# wl_phy_tx_secure register map
Vendor: Texas Instruments
Peripheral module from a debugger description file (folder CC35X1E).
Registers are 32-bit, access per field, reset 0x0 unless marked. A register's access mark holds for its fields unless they carry their own. Offsets are as the file gives them; lines under a group give offsets from that group; [hi:lo] are bit positions; {n}, {i} and the like mark numbered series; 'fields as' and 'values as' point back to an identical list; <NAME> marks a mode.

## wl_phy_tx_secure (part 1 of 2)
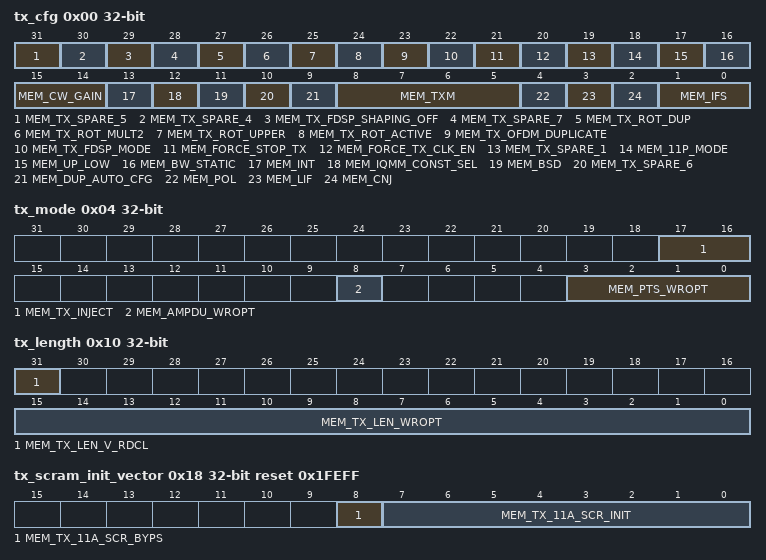
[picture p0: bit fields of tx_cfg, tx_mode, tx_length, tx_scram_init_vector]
0x00 tx_cfg rw reset not defined — Transmitter Configuration (TX_CFG) (0x1000)
  [31] MEM_TX_SPARE_5
  [30] MEM_TX_SPARE_4
  [29] MEM_TX_FDSP_SHAPING_OFF — An FDSP indication of whether to use spectral shaping or not. 0 - Spectral Shaping Enabled 1 - Spectral Shaping Disabled
  [28] MEM_TX_SPARE_7 — formerly: mem_tx_beamforming This bit is connected to the FDSP, and affects its behavior. Any other effect is TBD. 0 - Beamforming is off 1 - Beamforming is on
  [27] MEM_TX_ROT_DUP — Controls the 11b rotator. 0 - Tx LPM Regular: exp(2*pi*j*f*t) 1 - Tx LPM Duplication: cos(2*pi*f*t) Also known as lpm_sup_pos_mode
  [26] MEM_TX_ROT_MULT2 — Controls the 11b rotator. 0 - Tx LPM regular mode 1 - Tx LPM multiplies output by 2 (shift left one bit)
  [25] MEM_TX_ROT_UPPER — Controls the 11b rotator. 0 - Lower: The Tx LPM applies a -10 MHz frequency shift on the 11b signal 1 - Upper: The Tx LPM applies a +10 MHz frequency shift on the 11b signal
  [24] MEM_TX_ROT_ACTIVE — Controls the 11b rotator. 0 - The Tx LPM is Bypassed 1 - The Tx LPM is Active - Moves 11b to either upper (+10MHz) or lower (-10MHz)
  [23] MEM_TX_OFDM_DUPLICATE — Controls duplication of 20MHz OFDM signals in 40MHz channels. 0 - Either upper or lower. The other channel will be silent. 1 - Duplicate 20MHz signal to both upper and lower. According to the 11n standard, duplication of 20MHz wide OFDM signals is allowed in MCS32, and maybe for legacy (11a/g) signals too. The tx_ofdm_duplicate feature is not supported in 20MHz channels and for 40MHz wide 11n rates. It's not clear whether duplicating 11b signals is allowed. If required, use the mem_tx_rot_dup bit in this register (tx_cfg), since 11b is not an OFDM signal.
  [22] MEM_TX_FDSP_MODE — Select Tx FDSP mode or debug mode. 0 - The Tx OFDM will operate in debug mode. The Tx HW will transfer bins directly into the FFT, bypassing the FDSP and pre-FFT RAM. 1 - The Tx OFDM will operate in FDSP mode. The FDSP will process and send the bins to the FFT, through the pre-FFT RAM.
  [21] MEM_FORCE_STOP_TX — force_stop_tx - When force_stop_tx is asserted high the stop_tx is asserted. This bit is not self-clearing and the stop_tx will stay high until force_stop_tx is set back to 0. This feature can be useful in an attempt to reset the Tx-PHY, especially when a packet is not being transmitted. Can be used in conjuction with the force_tx_clk_en in order to make sure that clk_mod_80 is running while the stop_tx is being asserted.
  [20] MEM_FORCE_TX_CLK_EN — force_tx_clk_en - When force_tx_clk_en is asserted high the tx_clk_enable signal is asserted, which immediately turns on clk_mod_80, clk_mod_120 and clk_mod_60, which are the main Tx-PHY clocks. This bit is not self-clearing , meaning that the tx_clk_enable will stay high until force_tx_clk_en is set back to 0. The significance of this bit is that when the toggling of the Tx clock consumes a lot of power. The Tx module turns on the power automatically when a Tx packet is in progress, but for certain RAMs, like the Signal Generator's 'dwell' RAM, the mem_force_tx_clk_en bit may have to be temporarily set to 1. Remember to clear it to zero when finished.
  [19] MEM_TX_SPARE_1
  [18] MEM_11P_MODE — enable 11P mode where the transmit BW is only 10Mhz.
  [17] MEM_UP_LOW — When 40Mhz static BW is set with 20Mhz dynamic setting from MAC, this bit DEFINES where the 20Mhz BW is centered on the upper 10Mhz or lower 10Mhz of the all 40Mhz BW. 0 - Lower 20Mhz 1 - Upper 20Mhz
  [16] MEM_BW_STATIC — Static bandwidth setting based on the analog RF. 0 - 20Mhz BW. 1 - 40Mhz BW.
  [15:14] MEM_CW_GAIN — Controls the gain in CW mode 0 = x1/2 1= x1 2 = x2 3 = x4
  [13] MEM_INT — Enables the Interpolator if set to 1
  [12] MEM_IQMM_CONST_SEL — Selects whether IQ mismatch compensation and channel selection are obtained from tx_adi LUT or the fixed registers '0' - tx_adi LUT selection '1' - Register file constant selection ('override' values)
  [11] MEM_BSD — 802.11b Scrambler Disable Bit This bit is used to disable the scrambler in the 802.11b transmitter.0 - Scrambler is enabled.1 - Scrambler is disabled.
  [10] MEM_TX_SPARE_6 — A spare configuration bit for gate-level ECOs, or any other usage. ZZZZ Formerly the mem_BMS (see description below) ZZZZ IEEE 802.11b Length Field Select ZZZZ NOTE: This bit is no longer relevant. The read value is always '1'. ZZZZ The LENGTH field in the 802.11b header is specified in units of microseconds. This bit is used to select whether the PHY logic will convert the number of bytes and data rate into a value of microseconds. The alternative is to specify the microsecond value directly in register 0x100C. ZZZZ 0 - The hardware byte-to-usec converter (bytes2us) has been removed, so setting BMS to '0' is not allowed. ZZZZ 1 - Content of the MAC_LEGNTH_FIELD register (address 0x100C) is inserted into LENGTH field. The value must be calculated for every 11b packet.
  [9] MEM_DUP_AUTO_CFG — Selects between straightforward PHY configurations and automatic duplicate control for 11a/g and 11b according to the MAC's rate40 bit (mem_BW_wropt). 0 - Regular configuration; The user must set the mem_BW_wropt, mem_tx_ofdm_duplicate, mem_tx_rot_dup (and all other regs for that matter) dynamically (per packet), to choose between primary and duplicate. 1 - Automatic duplicate control for 11a/g and 11b according to the MAC's rate40 bit (mem_BW_wropt). In this mode - the values of the duplicate-Tx-control OCP-bits (mem_tx_ofdm_duplicate, mem_tx_rot_dup) are ignored for 11b and 11a/g frames. Duplicate transmission is, instead, controlled according to the mem_BW_wropt, as if it is the duplicate-tx--mode selection bit. This auto-config mechanism is necessary since the MAC/PHY interface doesn't have a duplicate-tx-mode control bit. This location in the tx_cfg OCP reg used to be: mem_BDO IEEE 802.11b Default Override When processing a packet using the 802.11b logic, the constraints of the IEEE 802.11b standard PPDU format may be disabled. Asserting this bit allows the use of register values to specify the SYNC field length, the SFD field content, and the scrambler seed.0 - Use IEEE 802.11b PPDU format.1 - Override default IEEE 802.11b PPDU format. Removed in Quattro.
  [8:5] MEM_TXM — Transmit Mode Select This field is used to determine the mode of transmitter operation. In addition to the normal transmission of packets, a number of test modes are also available to test operation of the 802.11a and 802.11b transmitters. 0000 - (M_IDLE) Idle mode. Used to disable the transmitter. This value may be written to terminate one of the other modes. 0001 - (M_TXDU) Enable the transmitter to process a PPDU. Normal operation. 0010 - (M_FDAC) Apply the forced register values (addresses 0x1047, 0x1048) to the I and Q DACs. There is a bug in the FORCE_DAC mode in the 1273 PG 1.0, so please do not use the FORCE_DAC mode without cosultation. 0011 - (M_TXPD) Carrier suppression mode. Used for testing the 802.11b transmitter. ( In 11a mode, this setting would transmit data which is programmed into the interleaver rams, but this option is no longer supported in the 1273 PG 1.0) 0100 - (M_TXCO) Transmit an 802.11a packet using constant data. Bits [15:8] of the SERVICE field register are applied to the input of the scrambler. 0101 - (M_TXCD) Transmit continuous data. Keep transmitting an 802.11a packet using continouos data. Bits [15:8] of the SERVICE field register are applied to the input of the scrambler. 0110 - (M_TXCW) Produce constant amplitude waves on data and pilot tone subcarriers. Used for testing the 802.11a transmitter. The guard interval must be set to 800ns in continuous wave mode, for the tones to be continuous on symbol boundaries. 0111 - Not supported in the 1273. This is the same as mode 0001, except that the transmitter clock starts running as soon as this value is written, and does not shut off after a packet has completed transmission. 1000 - Not suported in the 1273. (M_FFTS) FFT signal generator testmode. This mode is used to write signal data generated by the FFT module to the DACs.
  [4] MEM_POL — DAC Output Clock Polarity Select In the 1273 this bit is disconnected, therefore non-functional. This bit selects which edge of the clock is used to register transmitter outputs. 0 - Use positive clock edge to register output. 1 - Use negative clock edge to register output.
  [3] MEM_LIF — Low IF Centers the Transmitted output signal on 20MHz, instead of on the normal Zero-IF. During Low-IF - the I-output contains the low-IF modulated signal, while the Q-output is held at zero. Note - the Tx--Low-IF mode is incompatble with the Rx-Low-IF mode, which is centered on 5MHz.
  [2] MEM_CNJ — Conjugate Output Data Select This bit is used to select between the normal output to the DACs and one that is a conjugate of the complex number represented by the I and Q outputs.0 - Selects normal output to DACs.1 - Selects complex conjugate output to DACs.
  [1:0] MEM_IFS — MAC Interface Data Rate Control These bits determine the maximum rate of data byte transfer at the MAC interface. This only has an effect on 802.11a transmissions since the 802.11b data rates are much lower than those specified here. The control bits specify the rate as follows: 00 - 10 Mbytes per second 01 - 13 Mbytes per second 10 - RESERVED 11 - RESERVED
0x04 tx_mode — Transmitter Mode (TX_MODE) (0x1008) The TX_MODE register is a class 1 register. It must be valid before the Tx-PHY receives a start_tx signal. The Tx-PHY is triggered by a PreTx-to-Tx transition on the phy_mode wire, so the TX_MODE register must be written valid before that transition.
  [17:16] MEM_TX_INJECT rw — 0 - no inject, 1 - inject resampler in (40Mhz), 2- inject resampler out "
  [8] MEM_AMPDU_WROPT rw — Aggregated MPDU is transmitted in this PPDU.
  [3:0] MEM_PTS_WROPT rw — Field Name: PTS - Packet Type Select Field Values: PTS_11B_SHORT = 3'h0 PTS_11B_LONG = 3'h1 PTS_11A = 3'h2 PTS_11N_MM = 3'h3 PTS_11N_GF = 3'h4 PTS_11AX_SU = 3'h5 PTS_11AX_SU_ER = 3'h7 PTS_11AX_TB = 3'h8 PTS_11AX_TB_NDP = 3'h9 This field selects the Tx packet type which also tells the Tx-PHY the preamble type.
0x08 tx_data_rate — Transmitter Data Rate (TX_DATA_RATE) (0x100A) The TX_DATA_RATE is a class 1 register. It must be valid before the Tx-PHY receives a start_tx signal.
  [7:0] MEM_RATE_WROPT rw — In WL8 the rate feild for both Legacy and MCS are in the same byte and will be configured by the MAC accourding to the transmitted frame. (preamble type) below is explained how the RATE is interpeted for different modes. 802.11a,g Legacy Transmission Rate ========================= RATE[3:0] - This field specifies the rate of transmission of the data portion of the packet. 0xB 6 Mbps 0xF 9 Mbps 0xA 12 Mbps 0xE 18 Mbps 0x9 24 Mbps 0xD 36 Mbps 0x8 48 Mbps 0xC 54 Mbps RATE[4] - Reserved Bit (set to 0) This bit is inserted into the reserved bit of the SIGNAL field in the PPDU header. This bit can also be perceived as the fifth bit (MSB) of the 11a rate field, both in the TX_DATA_RATE register and in the SIG field itself. The 11a standard states that the Reserved bit shall be reserved for future use (11a 17.3.4.3), but does not define its value. The nine reserved bits in the SERVICE field are required to be zero (11a 17.3.5.1), with the sentence All reserved bits shall be set to zero . The example at the end (11a G.4.1) uses 0 as the reserved bit in the L-SIG. RATE[7:5] Unused and ignored. 802.11b mode ============ 802.11b PLCP Header Signal Field In addition to specifying the content of the SIGNAL field in the header, this field is used to configure the 802.11b transmitter logic to operate at the desired rate. 0x0A 1 Mbps 0x14 2 Mbps 0x37 5.5 Mbps 0x6E 11 Mbps 0xDC 22 Mbps 802.11n Mixed-Mode ================== In mixed-mode packets the RATE field must be set to RATE6 (0xB) and is configured internaly by the H/W MCS (Modulation Coding Scheme) ======================= 802.11n/11ax Transmission Rate Rate of transmission of the data portion of the packet. 0x00 - MCS 0 0x01 - MCS 1 0x02 - MCS 2 0x03 - MCS 3 0x04 - MCS 4 0x05 - MCS 5 0x06 - MCS 6 0x07 - MCS 7 0x08 - MCS 8 0x09 - MCS 9 0x0a - MCS 10 0x0b - MCS 11 0x0c - MCS 12 0x0d - MCS 13 0x0e - MCS 14 0x0f - MCS 15 0x20 - MCS 32
0x0C tx_service_11b — PLCP Header Service Field B(PLCP_SERVICE_FIELD_B) (0x100B) This is the 11b version of the SERVICE register. See also the PLCP_SERVICE_FIELD_A description.
  [7:0] MEM_TX_SERVICE_11B rw — for 11b Service the bits fields below are relevant: ----------------------------------------------------------------------- bit 0 - OFDM Select This bit is used to determine if CCK OFDM is used to transmit the PSDU. The TNETW1140 transmitter does not support CCK OFDM. 0 - Do not use CCK OFDM. 1 - Use CCK OFDM. bit 1 - Reserved Bit bit 2 - Locked Clock Select This bit indicates when the transmit frequency and symbol clocks are derived from the same oscillator.0 - Clocks are not locked.1 - Clocks are locked. bit 3 - Encoder Select This bit is used to select between CCK and PBCC encoding.0 - Use CCK encoding (only this option is available). bit 6:4 - Reserved Bit bit 7 - Lxt.
0x10 tx_length — Address: 0x1009 In 11a/b/g this register contains an unsigned integer indicating the number of PSDU bytes to be transferred from the MAC and processed for transmission. In 11n Mixed and GF this contains the HT length in bytes.
  [31] MEM_TX_LEN_V_RDCL ro — Bit 31 when set indicates to F/W that the length is valid it is also cleared on read.
  [15:0] MEM_TX_LEN_WROPT rw — 802.11n Mixed-Mode =============== The 12 LSBs are transmitted in the Length field of the L-SIG in a mixed-mode packet. 802.11n Greenfield =============== This field is ignored, since L-SIG is not transmitted. 802.11a Mode =============== Only bits [11:0] of this register are used for standard 802.11a modes. This value is inserted into the LENGTH field of the PLCP header. 802.11b Mode =============== All 16 bits of this register are used to define the packet length in bytes (octets). Note that the bytes-to-usec converter has been removed from hardware. The firmware must convert the byte-length to usec, then write the usec-length to MAC_LENGTH_FIELD register at address 0x100C.
0x14 tx_length_11b_usec — Provided Length in usec for 11B
  [15:0] MEM_LEN_11B_USEC rw — Cortex Provided Packet Length Field in usec. This register is used only in 11b packets. It is inserted into the LENGTH field of the 802.11b packet header when the BMS bit is set to one in the TX_CFG register, address 0x1000. Since the bytes2us converter has been removed, the BMS bit must always be set to one, and the MAC_LENGTH_FIELD must always be used.
0x18 tx_scram_init_vector reset 0x1FEFF (reset mask 0xFFFFFEFF) — Scrambler Initialization Vector
  [8] MEM_TX_11A_SCR_BYPS rw — Random Scrambler Select This bit controls whether the DSIV value is loaded. '0' - Load DSIV into the scrambler state register. The DSIV value is loaded when the byte_manip is off. The method of initializing the scrabmler register is therefore to clear the RND bit (to '0') and set the DSIV field to the desired reset value. Set the RND bit back to '1' with another write, in order to prevent having the scrambler state re-initialized at the end of the packet. Now the next packet will start with the chosen scrambler initial value. NOTE: Do not set an init value of 0000000, which would be equivalent to a bypassed scrambler. '1' - Do not load DSIV. 'Random' value is used. In this setting the scrambler state is not reset between packets.
  [7:0] MEM_TX_11A_SCR_INIT rw — 802.11a Data Scrambler Initialization Vector(bits 6:0) This value is loaded into the 802.11a data scrambler pseudo-random number generator prior to scrambling the PPDU data field during a transmit PPDU command or at the outset of the transmit continuous data command. See RND bit. Random Scrambler Select(bit 7) This bit controls whether the DSIV value is loaded. '0' - Load DSIV into the scrambler state register. The DSIV value is loaded when the byte_manip is off. The method of initializing the scrabmler register is therefore to clear the RND bit (to '0') and set the DSIV field to the desired reset value. Set the RND bit back to '1' with another write, in order to prevent having the scrambler state re-initialized at the end of the packet. Now the next packet will start with the chosen scrambler initial value. Note: Do not set an init value of 0000000, which would be equivalent to a bypassed scrambler. '1' - Do not load DSIV. 'Random' value is used. In this setting the scrambler state is not reset between packets.
0x1C tx_scram_state ro reset 0x3FFF — Scrambler state.
  [6:0] SCR_STATE — Scrambler state. from the byte manipluation block.
0x20 tx_table_indexes — This register holds the table indexs for several PHY tables for MULTI role support.
  [4:0] MEM_TX_POWER_IDX_WROPT rw — TX power table index , a.k.a power Levels
0x24 tx_header_cnt reset 0x320C8
  [9:0] MEM_TX_HEADER_CNT rw — Count 20M cycle from Tx rise till read 2'nd part of TxHeader (include Lengh field)
0x28 tx_service_ofdm — Tx service field for OFDM.
  [7:0] MEM_TX_SERVICE_OFDM rw — for OFDM Service the bits fields below are relevant: -------------------------------------------------------------------------- bits 6:0 - Scrambler Initialization Vector This value is used to initialize the scrambler on the receive side. It should normally be set to all-zeros. bits 7 - reserved.
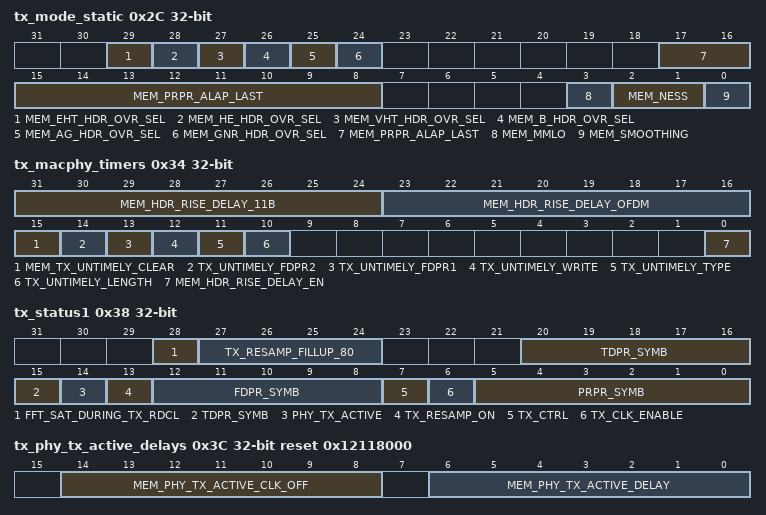
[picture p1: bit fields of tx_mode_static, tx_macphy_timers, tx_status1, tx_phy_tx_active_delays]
0x2C tx_mode_static reset not defined — TX mode register for bits which are used by the TX but are not intilized by the MAC.
  [29] MEM_EHT_HDR_OVR_SEL rw — Select the option to OVR (overide) static values of some EHT configuraion. The OVR value set by MMR - MEM_HDR_PARAM_OVR
  [28] MEM_HE_HDR_OVR_SEL rw — Select the option to OVR (overide) static values of some HE configuraion. The OVR value set by MMR - MEM_HDR_PARAM_OVR
  [27] MEM_VHT_HDR_OVR_SEL rw — Select the option to OVR (overide) static values of some HT/VHT configuraion. The OVR value set by MMR - MEM_HDR_PARAM_OVR
  [26] MEM_B_HDR_OVR_SEL rw — Select the option to OVR (overide) static values of some B configuraion. The OVR value set by MMR - MEM_HDR_PARAM_OVR
  [25] MEM_AG_HDR_OVR_SEL rw — Select the option to OVR (overide) static values of some A/G (Legacy) configuraion. The OVR value set by MMR - MEM_HDR_PARAM_OVR
  [24] MEM_GNR_HDR_OVR_SEL rw — Select the option to OVR (overide) static values of some General (GNR) configuraion. The OVR value set by MMR - MEM_HDR_PARAM_OVR
  [17:8] MEM_PRPR_ALAP_LAST rw — A 10 bit field that controls the 'As Late As Possible' (ALAP) delay. The ALAP counter delays the processing of the L-SIG from the ASAP (soonest) timing, to the ALAP timing. This provides the MAC with the longest possible period of time for writing the length fields. This field used to be set to 580, but then a series of FDSP packet types lowered the value to 570, 560, 500, then 450. Since there's not telling how difficult the situation may be, a configurable register field has been devised. Units: clk_120 cycles: 8.333 nsec.
  [3] MEM_MMLO rw — Mixed Mode L-SIG Override Selects L-SIG rate field source for Mixed-Mode packets. In mixed-mode, the rate field in the L-SIG must be set to RATE6 (0xB) (and the L-LENGTH to a matching spoofing value). 0 - The rate field in the L-SIG is taken from the RATE_SIG field in the TX_DATA_RATE. 1 - RATE6 is transmitted in the L-SIG rate field, ignoring the value of the RATE_SIG field in the TX_DATA_RATE register. The MMLO bit affects Tx-PHY behavior only in mixed-mode.
  [2:1] MEM_NESS rw — Number of Extension Spatial Streams: 0 - No Extension Spatial Streams 1 - One Extension Spatial Stream 2 - Two Extension Spatial Streams 3 - Three Extension Spatial Streams This field affects only the data showing up on the HT-SIG and nothing else. If you want a ZLF (zero length frame) set the legnth field/s to zero.
  [0] MEM_SMOOTHING rw — Set to 1 indicates that channel estimate smoothing is recommended. Set to 0 indicates that only per-carrier independent (unsmoothed) channel estimate is recommended. See 20.3.11.10.1 in 802.11n-2009 IEEE SPEC.
0x30 tx_rate_idx ro — A status register that accelerates lookup table conversion for the PHY cortex firmaware. Using this register the PHY firmware can initialize the Tx hardware faster for frame transmission.
  [5:0] TX_RATE_IDX — The status field that accelerates lookup table conversion for the PHY cortex firmaware. Using this register the PHY firmware can initialize the Tx hardware faster for frame transmission. This field's value is based on packet type, rate/MCS, static bandwidth (20/40), and rate-bandwidth (20/40). For more information ask Hanan Shomroni, Lior Shitrit, or have a look at: /cdb/wlanip45nm/modules/wl_phy_tx/hdl/rtl/wl_phy_rate_idx.v
0x34 tx_macphy_timers reset not defined
  [31:24] MEM_HDR_RISE_DELAY_11B rw — Sets the delay between tx_header rise and the start of Tx-PHY activity in the Tx 11b time domain. each unit equals 25ns (40MHz) Original architecture called for tx_header rise to actual start of packet on-air to be 4usec.
  [23:16] MEM_HDR_RISE_DELAY_OFDM rw — Sets the delay between tx_header rise and the start of Tx-PHY activity in the Tx OFDM time domain. each unit equals 25ns (40MHz) Original architecture called for tx_header rise to actual start of packet on-air to be 4usec.
  [15] MEM_TX_UNTIMELY_CLEAR rw — Clears the mem_tx_untimely_* sticky bits. Usage Instructions: 1. Turn on the digital Tx-PHY clock by setting the mem_force_tx_clk_en in the TX_CFG OCP reg to 1. 2. Set mem_tx_untimely_clear to 1 3. Clear mem_tx_untimely_clear to 0 4. Clear mem_force_tx_clk_en to 0
  [14] TX_UNTIMELY_FDPR2 ro — Sticky Bit: Rises if the FDPR is not ready when the TDPR needs to start a symbol. Cleared using mem_tx_untimely_clear (see the instructions).
  [13] TX_UNTIMELY_FDPR1 ro — Sticky Bit: Rises if the FDPR is not ready when the TDPR needs to start the first symbol according to the 4usec timer (mem_tx_hdr_timer_val). Doens't work in FPGA mode (27/04/2011). Cleared using mem_tx_untimely_clear (see the instructions).
  [12] TX_UNTIMELY_WRITE ro — Sticky Bit: Rises due to a write to an OCP register (other than the length regs) when the Tx-PHY is active and processing. Cleared using mem_tx_untimely_clear (see the instructions).
  [11] TX_UNTIMELY_TYPE ro — As of 27/04/2011 this bit is still not implemented. Its value is identical to tx_untimely_length. Sticky Bit: Rises due to a change to the packet type registers when the Tx-PHY is active and processing. Cleared using mem_tx_untimely_clear (see the instructions).
  [10] TX_UNTIMELY_LENGTH ro — Sticky Bit: Rises due to a change to the length registers during SIG or Data processing. The length registers are TX_LENGTH, TX_LENGTH_11B_USEC, and TX_LENGTH_SPOOF. Cleared using mem_tx_untimely_clear (see the instructions).
  [0] MEM_HDR_RISE_DELAY_EN rw — Choose whether to use the hdr_timer or not. The hdr_timer sets the delay between tx_header rise and the start of Tx-PHY activity (OFDM or 11b) in the Tx time domain. Original architecture called for tx_header rise to actual start of packet on-air to be 4usec. 0 - The hdr_timer is disabled. The Tx will start ASAP 1 - The hdr_timer is enabled. start_tx will be delayed according to See the mem_tx_hdr_timer_ofdm/11bl field
0x38 tx_status1 ro — A varied mix of Tx-PHY status indications. For debug purposes only. May be bug-prone, due to clock domain interchanges. Not for FW or SW purposes, only for debug. The signals and wires are served to you direct from the RTL.
  [28] FFT_SAT_DURING_TX_RDCL
  [27:24] TX_RESAMP_FILLUP_80 — Tx resampler FIFO fillup indicator. It's going to be either fillup_80_i0 or fillup_80_i1, according to the fillup_80_for_swallow_sel, according to mem_tx_clk80_swallow_sel. See the TX_TDPR_CONFIG OCP register for further details.
  [20:15] TDPR_SYMB
  [14] PHY_TX_ACTIVE
  [13] TX_RESAMP_ON
  [12:8] FDPR_SYMB
  [7] TX_CTRL
  [6] TX_CLK_ENABLE
  [5:0] PRPR_SYMB
0x3C tx_phy_tx_active_delays reset 0x12118000 (reset mask 0xFFFF8000) — phy_tx_active delays register
  [14:8] MEM_PHY_TX_ACTIVE_CLK_OFF rw — Sets the delay that is inserted between Tx-PHY time domain activity and the Tx-PHY clock being turned off. One this delay elapses, a tx_complete signal is emitted, which triggers stop_tx and also tx_clk_enable de-assertion. Units: 12.5nsec (clk_80) Set to a larger value than mem_phy_tx_active_delay.
  [6:0] MEM_PHY_TX_ACTIVE_DELAY rw — Sets the delay that is inserted between Tx-PHY time domain activity and the phy_tx_active that is sent to the MAC and used for other system needs. This delay is used to emulate the Tx DFE, analog baseband, mixer and power amplifier delay, so that phy_tx_active can depict actual Tx on-air as accurately as possible. Units: 12.5nsec (clk_80) Set to a smaller value than mem_phy_tx_active_clk_off. If you need a larger mem_phy_tx_active_delay, simply add the same amount of time (clock cycles) to mem_phy_tx_active_clk_off.
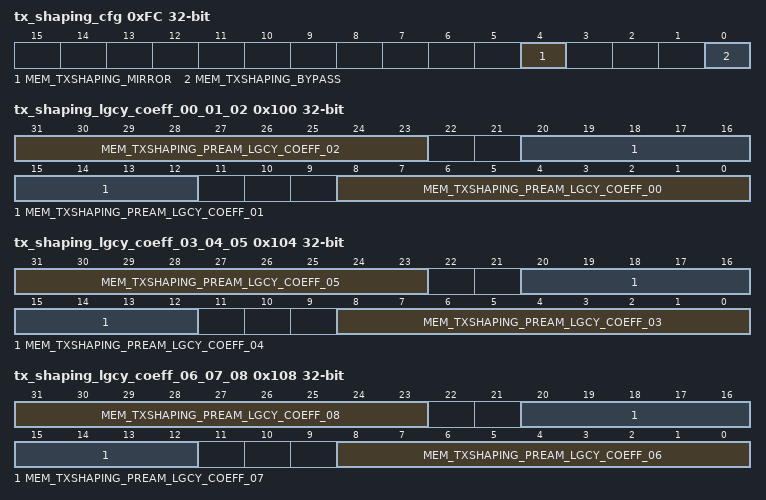
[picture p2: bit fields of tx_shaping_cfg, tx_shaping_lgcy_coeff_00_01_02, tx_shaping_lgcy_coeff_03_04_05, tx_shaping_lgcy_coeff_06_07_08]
0xFC tx_shaping_cfg — General Shaping Configuration MMR - to configurate Shaping modes and options
  [4] MEM_TXSHAPING_MIRROR rw — Shaping Mirror Mode: 0 - Mirror Disable 1 - Mirror Enable
  [0] MEM_TXSHAPING_BYPASS rw — Tx-Shaping Bypass mode: 0 - Shaping Operational 1 - Shaping in Bypass-Mode (not working)
0x100 tx_shaping_lgcy_coeff_00_01_02 reset not defined — Part of the 28 coeffs for the legacy part of the preamble.
  [31:23] MEM_TXSHAPING_PREAM_LGCY_COEFF_02 rw — Part of the 28 coeffs for the legacy part of the preamble. <1.8u>
  [20:12] MEM_TXSHAPING_PREAM_LGCY_COEFF_01 rw — Part of the 28 coeffs for the legacy part of the preamble. <1.8u>
  [8:0] MEM_TXSHAPING_PREAM_LGCY_COEFF_00 rw — Part of the 28 coeffs for the legacy part of the preamble. <1.8u>
0x104 tx_shaping_lgcy_coeff_03_04_05 reset not defined — Part of the 28 coeffs for the legacy part of the preamble.
  [31:23] MEM_TXSHAPING_PREAM_LGCY_COEFF_05 rw — Part of the 28 coeffs for the legacy part of the preamble. <1.8u>
  [20:12] MEM_TXSHAPING_PREAM_LGCY_COEFF_04 rw — Part of the 28 coeffs for the legacy part of the preamble. <1.8u>
  [8:0] MEM_TXSHAPING_PREAM_LGCY_COEFF_03 rw — Part of the 28 coeffs for the legacy part of the preamble. <1.8u>
0x108 tx_shaping_lgcy_coeff_06_07_08 reset not defined — Part of the 28 coeffs for the legacy part of the preamble.
  [31:23] MEM_TXSHAPING_PREAM_LGCY_COEFF_08 rw — Part of the 28 coeffs for the legacy part of the preamble. <1.8u>
  [20:12] MEM_TXSHAPING_PREAM_LGCY_COEFF_07 rw — Part of the 28 coeffs for the legacy part of the preamble. <1.8u>
  [8:0] MEM_TXSHAPING_PREAM_LGCY_COEFF_06 rw — Part of the 28 coeffs for the legacy part of the preamble. <1.8u>
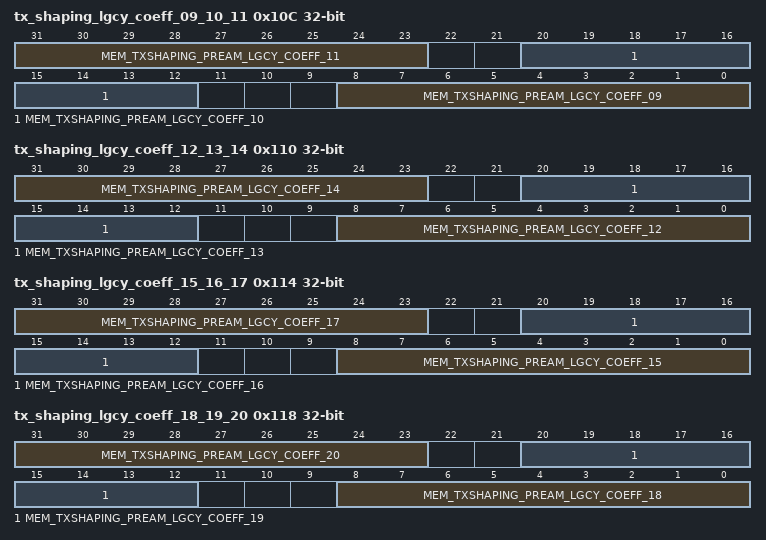
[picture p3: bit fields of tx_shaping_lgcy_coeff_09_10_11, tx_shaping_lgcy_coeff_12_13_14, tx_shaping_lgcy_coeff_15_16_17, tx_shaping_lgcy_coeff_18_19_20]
0x10C tx_shaping_lgcy_coeff_09_10_11 reset not defined — Part of the 28 coeffs for the legacy part of the preamble.
  [31:23] MEM_TXSHAPING_PREAM_LGCY_COEFF_11 rw — Part of the 28 coeffs for the legacy part of the preamble. <1.8u>
  [20:12] MEM_TXSHAPING_PREAM_LGCY_COEFF_10 rw — Part of the 28 coeffs for the legacy part of the preamble. <1.8u>
  [8:0] MEM_TXSHAPING_PREAM_LGCY_COEFF_09 rw — Part of the 28 coeffs for the legacy part of the preamble. <1.8u>
0x110 tx_shaping_lgcy_coeff_12_13_14 reset not defined — Part of the 28 coeffs for the legacy part of the preamble.
  [31:23] MEM_TXSHAPING_PREAM_LGCY_COEFF_14 rw — Part of the 28 coeffs for the legacy part of the preamble. <1.8u>
  [20:12] MEM_TXSHAPING_PREAM_LGCY_COEFF_13 rw — Part of the 28 coeffs for the legacy part of the preamble. <1.8u>
  [8:0] MEM_TXSHAPING_PREAM_LGCY_COEFF_12 rw — Part of the 28 coeffs for the legacy part of the preamble. <1.8u>
0x114 tx_shaping_lgcy_coeff_15_16_17 reset not defined — Part of the 28 coeffs for the legacy part of the preamble.
  [31:23] MEM_TXSHAPING_PREAM_LGCY_COEFF_17 rw — Part of the 28 coeffs for the legacy part of the preamble. <1.8u>
  [20:12] MEM_TXSHAPING_PREAM_LGCY_COEFF_16 rw — Part of the 28 coeffs for the legacy part of the preamble. <1.8u>
  [8:0] MEM_TXSHAPING_PREAM_LGCY_COEFF_15 rw — Part of the 28 coeffs for the legacy part of the preamble. <1.8u>
0x118 tx_shaping_lgcy_coeff_18_19_20 reset not defined — Part of the 28 coeffs for the legacy part of the preamble.
  [31:23] MEM_TXSHAPING_PREAM_LGCY_COEFF_20 rw — Part of the 28 coeffs for the legacy part of the preamble. <1.8u>
  [20:12] MEM_TXSHAPING_PREAM_LGCY_COEFF_19 rw — Part of the 28 coeffs for the legacy part of the preamble. <1.8u>
  [8:0] MEM_TXSHAPING_PREAM_LGCY_COEFF_18 rw — Part of the 28 coeffs for the legacy part of the preamble. <1.8u>
